# STM32F105xC register map
File version: 1.0
Registers are 32-bit, read-write, reset 0x0 unless marked. A register's access mark holds for its fields unless they carry their own. Offsets are from the block's base; [hi:lo] are bit positions; {n}, {i} and the like mark numbered series.

## OB — Option Bytes Registers
Base 0x1FFFF800
0x00 RDP 16-bit
0x02 USER 16-bit
0x04 Data0 16-bit
0x06 Data1 16-bit
{0x8+2i} WRP{i} 16-bit (i=0..3)

## TIM6 — TIM Timers
Base 0x40001000
Same registers: TIM7 0x40001400
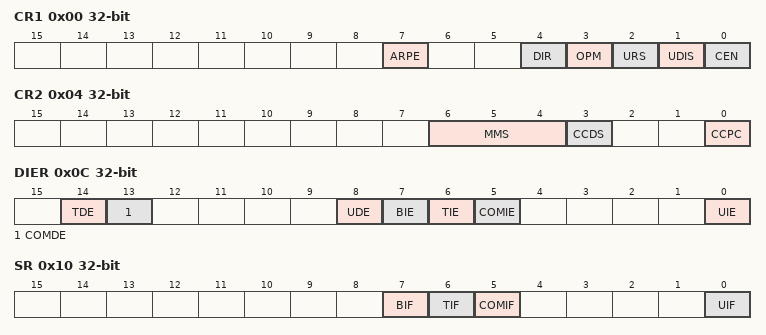
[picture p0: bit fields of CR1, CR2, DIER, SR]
0x00 CR1 — TIM control register 1
  [7] ARPE — Auto-reload preload enable
  [4] DIR — Direction
    0=UP (Timer counter counts up); 1=DOWN (Timer counter counts down)
  [3] OPM — One pulse mode
    1=SINGLE (Counter stops counting at the next update event); 0=REPETITIVE (Counter is not stopped at update event)
  [2] URS — Update request source
    0=REGULAR (Counter overflow/underflow, Setting the UG bit or Update generation through the slave mode controller generates an update request); 1=COUNTER (Only counter overflow/underflow generates an update request)
  [1] UDIS — Update disable
  [0] CEN — Counter enable
0x04 CR2 — TIM control register 2
  [6:4] MMS — MMS[2:0] bits (Master Mode Selection)
    0=RESET (UG bit from the TIMx_EGR register is used as trigger output); 1=ENABLE (Counter Enable signal (CNT_EN) is used as trigger output); 2=UPDATE (Update event is used as trigger output); 3=CC1IF (CC1 capture or a compare match is used as trigger output); {v}=OC{v-3}REF (OC{v-3}REF signal is used as trigger output) (v=4..7)
  [3] CCDS — Capture/Compare DMA Selection
    0=CC (CCx DMA request sent when CCx event occurs); 1=UPDATE (CCx DMA requests sent when update event occurs)
  [0] CCPC — Capture/Compare Preloaded Control
0x0C DIER — TIM DMA/interrupt enable register
  [14] TDE — Trigger DMA request enable
  [13] COMDE — COM DMA request enable
  [8] UDE — Update DMA request enable
  [7] BIE — Break interrupt enable
  [6] TIE — Trigger interrupt enable
  [5] COMIE — COM interrupt enable
  [0] UIE — Update interrupt enable
0x10 SR — TIM status register
  [7] BIF — Break interrupt Flag
  [6] TIF — Trigger interrupt Flag
  [5] COMIF — COM interrupt Flag
  [0] UIF — Update interrupt Flag
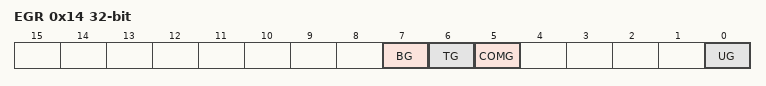
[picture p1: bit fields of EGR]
0x14 EGR — TIM event generation register
  [7] BG — Break Generation
  [6] TG — Trigger Generation
  [5] COMG — Capture/Compare Control Update Generation
  [0] UG — Update Generation
0x24 CNT — TIM counter register
  [31:0] CNT — Counter Value
0x28 PSC — TIM prescaler register
  [15:0] PSC — Prescaler Value
0x2C ARR — TIM auto-reload register
  [31:0] ARR — actual auto-reload Value
0x4C DMAR — TIM DMA address for full transfer register
  [15:0] DMAB — DMA register for burst accesses
0x50 OR — TIM option register

## RTC — Real-Time Clock
Base 0x40002800
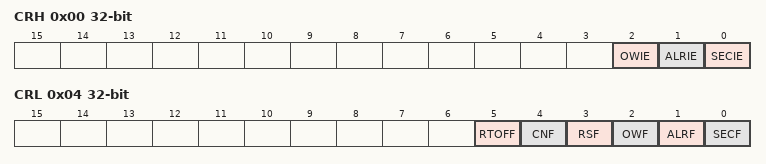
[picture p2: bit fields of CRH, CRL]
0x00 CRH
  [2] OWIE — OverfloW Interrupt Enable
  [1] ALRIE — Alarm Interrupt Enable
  [0] SECIE — Second Interrupt Enable
0x04 CRL
  [5] RTOFF — RTC operation OFF
  [4] CNF — Configuration Flag
  [3] RSF — Registers Synchronized Flag
  [2] OWF — OverfloW Flag
  [1] ALRF — Alarm Flag
  [0] SECF — Second Flag
0x08 PRLH
  [3:0] PRL — RTC Prescaler Reload Value High
0x0C PRLL
  [15:0] PRL — RTC Prescaler Reload Value Low
0x10 DIVH
  [3:0] RTC_DIV — RTC Clock Divider High
0x14 DIVL
  [15:0] RTC_DIV — RTC Clock Divider Low
0x18 CNTH
  [15:0] RTC_CNT — RTC Counter High
0x1C CNTL
  [15:0] RTC_CNT — RTC Counter Low
0x20 ALRH
  [15:0] RTC_ALR — RTC Alarm High
0x24 ALRL
  [15:0] RTC_ALR — RTC Alarm Low

## WWDG — Window WATCHDOG
Base 0x40002C00
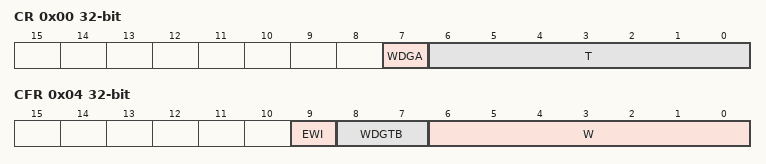
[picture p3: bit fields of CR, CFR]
0x00 CR — WWDG Control register
  [7] WDGA — Activation bit
  [6:0] T — T[6:0] bits (7-Bit counter (MSB to LSB))
0x04 CFR — WWDG Configuration register
  [9] EWI — Early Wakeup Interrupt
  [8:7] WDGTB — WDGTB[1:0] bits (Timer Base)
    0=PRESCALER_1 (WWDG counter clock = (PCLK1/4096)/1); 1=PRESCALER_2 (WWDG counter clock = (PCLK1/4096)/2); 2=PRESCALER_4 (WWDG counter clock = (PCLK1/4096)/4); 3=PRESCALER_8 (WWDG counter clock = (PCLK1/4096)/8)
  [6:0] W — W[6:0] bits (7-bit window value)
0x08 SR — WWDG Status register
  [0] EWIF — Early Wakeup Interrupt Flag
